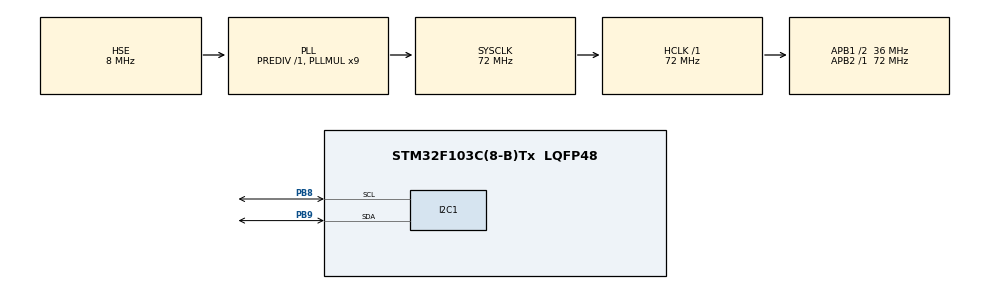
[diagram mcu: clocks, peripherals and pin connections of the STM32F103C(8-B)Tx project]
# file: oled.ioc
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Dma.I2C1_TX.0.Direction=DMA_MEMORY_TO_PERIPH
Dma.I2C1_TX.0.Instance=DMA1_Channel6
Dma.I2C1_TX.0.MemDataAlignment=DMA_MDATAALIGN_BYTE
Dma.I2C1_TX.0.MemInc=DMA_MINC_ENABLE
Dma.I2C1_TX.0.Mode=DMA_NORMAL
Dma.I2C1_TX.0.PeriphDataAlignment=DMA_PDATAALIGN_BYTE
Dma.I2C1_TX.0.PeriphInc=DMA_PINC_DISABLE
Dma.I2C1_TX.0.Priority=DMA_PRIORITY_LOW
Dma.Request0=I2C1_TX
I2C1.I2C_Mode=I2C_Fast
Mcu.Family=STM32F1
Mcu.Name=STM32F103C(8-B)Tx
Mcu.Package=LQFP48
NVIC.DMA1_Channel6_IRQn=true\:0\:0\:false\:false\:true\:false\:true\:true
NVIC.I2C1_ER_IRQn=true\:0\:0\:false\:false\:true\:true\:true\:true
NVIC.I2C1_EV_IRQn=true\:0\:0\:false\:false\:true\:true\:true\:true
NVIC.PriorityGroup=NVIC_PRIORITYGROUP_4
PA13.Mode=Serial_Wire
PA13.Signal=SYS_JTMS-SWDIO
PA14.Mode=Serial_Wire
PA14.Signal=SYS_JTCK-SWCLK
PB8.GPIO_Speed=GPIO_SPEED_FREQ_HIGH
PB8.Mode=I2C
PB8.Signal=I2C1_SCL
PB9.GPIO_Speed=GPIO_SPEED_FREQ_HIGH
PB9.Mode=I2C
PB9.Signal=I2C1_SDA
PC14-OSC32_IN.Mode=LSE-External-Oscillator
PC14-OSC32_IN.Signal=RCC_OSC32_IN
PC15-OSC32_OUT.Mode=LSE-External-Oscillator
PC15-OSC32_OUT.Signal=RCC_OSC32_OUT
PD0-OSC_IN.Mode=HSE-External-Oscillator
PD0-OSC_IN.Signal=RCC_OSC_IN
PD1-OSC_OUT.Mode=HSE-External-Oscillator
PD1-OSC_OUT.Signal=RCC_OSC_OUT
ProjectManager.HeapSize=0x200
ProjectManager.StackSize=0x400
ProjectManager.TargetToolchain=CMake
RCC.AHBFreq_Value=72000000
RCC.APB1CLKDivider=RCC_HCLK_DIV2
RCC.APB1Freq_Value=36000000
RCC.APB1TimFreq_Value=72000000
RCC.APB2Freq_Value=72000000
RCC.APB2TimFreq_Value=72000000
RCC.HCLKFreq_Value=72000000
RCC.PLLMUL=RCC_PLL_MUL9
RCC.PLLSourceVirtual=RCC_PLLSOURCE_HSE
RCC.SYSCLKFreq_VALUE=72000000
RCC.SYSCLKSource=RCC_SYSCLKSOURCE_PLLCLK
RCC.USBFreq_Value=72000000
board=custom

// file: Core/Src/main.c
/* USER CODE BEGIN Header */
/**
  ******************************************************************************
  * @file           : main.c
  * @brief          : Main program body
  ******************************************************************************
  * @attention
  *
  * Copyright (c) 2026 STMicroelectronics.
  * All rights reserved.
  *
  * This software is licensed under terms that can be found in the LICENSE file
  * in the root directory of this software component.
  * If no LICENSE file comes with this software, it is provided AS-IS.
  *
  ******************************************************************************
  */
/* USER CODE END Header */
#include "main.h"
#include "dma.h"
#include "i2c.h"
#include "gpio.h"

/* USER CODE BEGIN Includes */
#include "oled.h"
#include "oled_font.h"
/* USER CODE END Includes */

void SystemClock_Config(void);

int main(void)
{

  /* MCU Configuration--------------------------------------------------------*/

  /* Reset of all peripherals, Initializes the Flash interface and the Systick. */
  HAL_Init();

  /* Configure the system clock */
  SystemClock_Config();

  /* Initialize all configured peripherals */
  MX_GPIO_Init();
  MX_DMA_Init();
  MX_I2C1_Init();
  /* USER CODE BEGIN 2 */
  OLED_S oled;
  OLED_CFG_S cfg = {
    .hi2c      = &hi2c1,
    .dev_addr  = OLED_ADDR_78   // 默认地址, 可选 OLED_ADDR_7A
  };
  OLED_Create(&oled, &cfg);

  /* ====== 几何绘制测试 ====== */

  /* 1. 水平线: y=5, 从 x=10 到 x=117 */
  oled.draw_hline(&oled, 10, 117, 5);

  /* 2. 垂直线: x=5, 从 y=10 到 y=53 */
  oled.draw_vline(&oled, 5, 10, 53);

  /* 3. 斜线: 从左上到右下 (对角线) */
  oled.draw_line(&oled, 10, 10, 117, 53);

  /* 4. 空心矩形: 左上(20,20), 宽40, 高20 */
  oled.draw_rect(&oled, 20, 20, 40, 20, 0);

  /* 5. 空心圆: 圆心(100,30), 半径15 */
  oled.draw_circle(&oled, 100, 30, 15, 0);

  /* 6. 实心矩形: 左上(70,40), 宽30, 高10 */
  oled.draw_rect(&oled, 70, 40, 30, 10, 1);

  /* 7. 实心圆: 圆心(30,45), 半径8 */
  oled.draw_circle(&oled, 30, 45, 8, 1);

  /* 8. 标签文字 */
  oled.show_str(&oled, 0, 56, "H V L R0 C0 R1 C1", 1);

  /* 一次性刷新到硬件 */
  oled.refresh_dma(&oled);
  oled.clear(&oled);
  HAL_Delay(3000);

  /* 中文显示测试 */
  oled.show_cn(&oled, 0, 16, "嵌入式学习");
  oled.refresh_dma(&oled);
  oled.clear(&oled);
  HAL_Delay(3000);
  /* USER CODE END 2 */

  /* Infinite loop */
  /* USER CODE BEGIN WHILE */
  while (1)
  {
    /* 图片显示测试 */
    for (uint8_t i = 0; i < 10; i++)
    {
      oled.show_bmp(&oled, 0, 0, 52, 48, astronaut[i]);
      oled.refresh_dma(&oled);
      HAL_Delay(100);
    }
    /* USER CODE END WHILE */

  }
}

void SystemClock_Config(void)
{
  RCC_OscInitTypeDef RCC_OscInitStruct = {0};
  RCC_ClkInitTypeDef RCC_ClkInitStruct = {0};

  /** Initializes the RCC Oscillators according to the specified parameters
  * in the RCC_OscInitTypeDef structure.
  */
  RCC_OscInitStruct.OscillatorType = RCC_OSCILLATORTYPE_HSE;
  RCC_OscInitStruct.HSEState = RCC_HSE_ON;
  RCC_OscInitStruct.HSEPredivValue = RCC_HSE_PREDIV_DIV1;
  RCC_OscInitStruct.HSIState = RCC_HSI_ON;
  RCC_OscInitStruct.PLL.PLLState = RCC_PLL_ON;
  RCC_OscInitStruct.PLL.PLLSource = RCC_PLLSOURCE_HSE;
  RCC_OscInitStruct.PLL.PLLMUL = RCC_PLL_MUL9;
  if (HAL_RCC_OscConfig(&RCC_OscInitStruct) != HAL_OK)
  {
    Error_Handler();
  }

  /** Initializes the CPU, AHB and APB buses clocks
  */
  RCC_ClkInitStruct.ClockType = RCC_CLOCKTYPE_HCLK|RCC_CLOCKTYPE_SYSCLK
                              |RCC_CLOCKTYPE_PCLK1|RCC_CLOCKTYPE_PCLK2;
  RCC_ClkInitStruct.SYSCLKSource = RCC_SYSCLKSOURCE_PLLCLK;
  RCC_ClkInitStruct.AHBCLKDivider = RCC_SYSCLK_DIV1;
  RCC_ClkInitStruct.APB1CLKDivider = RCC_HCLK_DIV2;
  RCC_ClkInitStruct.APB2CLKDivider = RCC_HCLK_DIV1;

  if (HAL_RCC_ClockConfig(&RCC_ClkInitStruct, FLASH_LATENCY_2) != HAL_OK)
  {
    Error_Handler();
  }
}

void Error_Handler(void)
{
  __disable_irq();
  while (1)
  {
  }
}
